# W600 register map
Vendor: Winner Micro; Series: W60X; File version: 1.0
ARM 32-bit Cortex-M3 based device
CPU: CM3 r2p1, little endian, no MPU, no FPU, 3 interrupt priority bits
Registers are 32-bit, read-write, reset 0x0 unless marked. A register's access mark holds for its fields unless they carry their own. Offsets are from the block's base; lines under a group give offsets from that group; [hi:lo] are bit positions; {n}, {i} and the like mark numbered series; 'fields as' and 'values as' point back to an identical list; <NAME> marks a mode.

## Memory map
0x40000700 RCC size 0x20 — Reset and clock control
0x40010C00 GPIOA size 0x3C — general-purpose I/O
0x40011200 GPIOB size 0x3C

## Interrupts
6 GPIOA — GPIO A combined interrupt

## RCC — Reset and clock control
Base 0x40000700
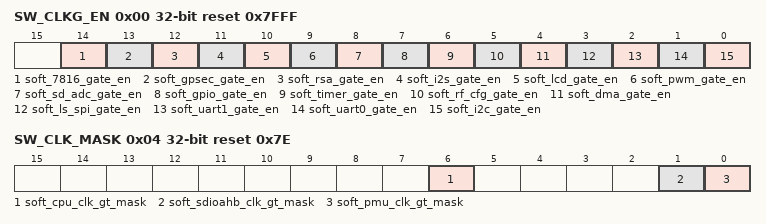
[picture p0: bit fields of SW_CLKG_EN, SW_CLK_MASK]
0x00 SW_CLKG_EN reset 0x7FFF — Software clock gating enable register
  [14] soft_7816_gate_en — 7816/uart2 clock
  [13] soft_gpsec_gate_en — 7816/uart2
  [12] soft_rsa_gate_en — 7816/uart2
  [11] soft_i2s_gate_en — 7816/uart2
  [10] soft_lcd_gate_en — lcd clock
  [9] soft_pwm_gate_en — pwm clock
  [8] soft_sd_adc_gate_en — sd_adc clock
  [7] soft_gpio_gate_en — gpio clock
  [6] soft_timer_gate_en — timer clock
  [5] soft_rf_cfg_gate_en — rf_cfg clock: internal use, do not modify
  [4] soft_dma_gate_en — dma clock
  [3] soft_ls_spi_gate_en — low speed spi clock
  [2] soft_uart1_gate_en — uart1 clock
  [1] soft_uart0_gate_en — uart0 clock
  [0] soft_i2c_gate_en — i2c clock
0x04 SW_CLK_MASK reset 0x7E — Software clock mask register
  [6] soft_cpu_clk_gt_mask — Indicates whether the clock supplied to the CPU clock domain (including CPU, bus1, ROM and SRAM) can be turned off adaptively.
  [1] soft_sdioahb_clk_gt_mask — Indicates whether the clock supplied to the sdio ahb clock domain can be turned off adaptively.
  [0] soft_pmu_clk_gt_mask — The clock output from the pll is followed by a gating unit, using this register configuration to indicate whether it is allowed to be shut down by the PMU.
0x0C SW_RST_CTRL reset 0x1FFFFFF — Software reset control register
0x10 SYS_CLK_DIV reset 0x2212 — Clock divider configuration register
0x14 DEBUG_CTRL — Debug control register
0x18 I2S_CLK_CTRL — I2S clock control register

## GPIOA — general-purpose I/O
Base 0x40010C00
0x00 DATA reset 0x180B
0x04 DATA_EN reset 0xFFFF — Data enable register
0x08 DIR — Direction control register
0x0C PULL_EN reset 0xFFFF — Up and down control register
0x10 AF_SEL reset 0xFFFF — Multiplex select register
0x14 SF_S1 — Multiplex select register 1
0x18 AF_S0 — Multiplex select register 0
0x20 IS — Interrupt trigger mode configuration register
0x24 IBE — Interrupt edge trigger mode configuration register
0x28 IEV — Interrupt upper and lower edge trigger configuration register
0x2C IE — Interrupt enable configuration register
0x30 RIS ro — Bare interrupt status register
0x38 IC wo write-1-clears — Interrupt clear control register
0x34C MIS ro — Interrupt status register after masking

## GPIOB
Base 0x40011200
Registers as GPIOA; these are added or differ:
0x00 DATA reset 0x7304
0x04 DATA_EN reset 0x7FFFFFFF — Data enable register

## Licence text in the file
ARM Limited (ARM) is supplying this software for use with Cortex-M processor based microcontroller, but can be equally used for other suitable processor architectures. This file can be freely distributed. Modifications to this file shall be clearly marked. . THIS SOFTWARE IS PROVIDED "AS IS". NO WARRANTIES, WHETHER EXPRESS, IMPLIED. OR STATUTORY, INCLUDING, BUT NOT LIMITED TO, IMPLIED WARRANTIES OF. MERCHANTABILITY AND FITNESS FOR A PARTICULAR PURPOSE APPLY TO THIS SOFTWARE. ARM SHALL NOT, IN ANY CIRCUMSTANCES, BE LIABLE FOR SPECIAL, INCIDENTAL, OR. CONSEQUENTIAL DAMAGES, FOR ANY REASON WHATSOEVER.

## Notices in the file
Copyright (C) 2012-2014 ARM Limited. All rights reserved.
Purpose: System Viewer Description (SVD) Example (Schema Version 1.1)
This is a description of a none-existent and incomplete device
for demonstration purposes only.
Redistribution and use in source and binary forms, with or without
modification, are permitted provided that the following conditions are met:
- Redistributions of source code must retain the above copyright
notice, this list of conditions and the following disclaimer.
- Redistributions in binary form must reproduce the above copyright
notice, this list of conditions and the following disclaimer in the
documentation and/or other materials provided with the distribution.
- Neither the name of ARM nor the names of its contributors may be used
to endorse or promote products derived from this software without
specific prior written permission.
THIS SOFTWARE IS PROVIDED BY THE COPYRIGHT HOLDERS AND CONTRIBUTORS "AS IS"
AND ANY EXPRESS OR IMPLIED WARRANTIES, INCLUDING, BUT NOT LIMITED TO, THE
ARE DISCLAIMED. IN NO EVENT SHALL COPYRIGHT HOLDERS AND CONTRIBUTORS BE
LIABLE FOR ANY DIRECT, INDIRECT, INCIDENTAL, SPECIAL, EXEMPLARY, OR
CONSEQUENTIAL DAMAGES (INCLUDING, BUT NOT LIMITED TO, PROCUREMENT OF
SUBSTITUTE GOODS OR SERVICES; LOSS OF USE, DATA, OR PROFITS; OR BUSINESS
INTERRUPTION) HOWEVER CAUSED AND ON ANY THEORY OF LIABILITY, WHETHER IN
CONTRACT, STRICT LIABILITY, OR TORT (INCLUDING NEGLIGENCE OR OTHERWISE)
ARISING IN ANY WAY OUT OF THE USE OF THIS SOFTWARE, EVEN IF ADVISED OF THE
POSSIBILITY OF SUCH DAMAGE.
